# COUNTER_32K register map
Vendor: Texas Instruments
Peripheral module from a debugger description file (folder omap5430_ES2_PUBLIC).
Registers are 32-bit, read-only, no defined reset value unless marked. A register's access mark holds for its fields unless they carry their own. Offsets are as the file gives them; lines under a group give offsets from that group; [hi:lo] are bit positions; {n}, {i} and the like mark numbered series; 'fields as' and 'values as' point back to an identical list; <NAME> marks a mode.

## COUNTER_32K
0x00 REVISION — This register contains the sync counter IP revision code.
  [31:0] REV — IP revision
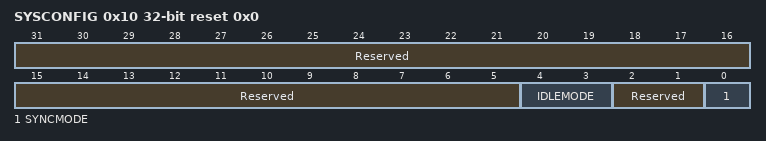
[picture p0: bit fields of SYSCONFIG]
0x10 SYSCONFIG access per field reset 0x0 — This register is used for idle modes only.
  [31:5] Reserved ro — Reads return 0.
  [4:3] IDLEMODE rw — Power management REQ/ACK control
  [2:1] Reserved ro — Reads return 0.
  [0] SYNCMODE rw — Synchronization scheme
0x30 CR reset 0x3 — This register contains the 32-kHz sync counter value.
  [31:0] COUNTER_VALUE — Counter register value
